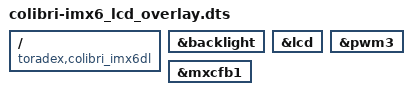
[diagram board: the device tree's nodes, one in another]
// Enable the parallel RGB interface on the Colibri iMX6DL

/dts-v1/;
/plugin/;

/ {
	compatible = "toradex,colibri_imx6dl",
		     "toradex,colibri-imx6dl";
};

&backlight {
    status = "okay";
};

&lcd {
    status = "okay";
};

&mxcfb1 {
    status = "okay";
};

&pwm3 {
    status = "okay";
};
